# ESP32-P4 register map
Vendor: ESPRESSIF SYSTEMS (SHANGHAI) CO., LTD.; Series: ESP32 P-Series; File version: 3
CPU: RV32IMAFC r0p0, little endian, no MPU, FPU, 0 interrupt priority bits
Address unit: 32 bits
Registers are 32-bit, read-write, reset 0x0 unless marked. A register's access mark holds for its fields unless they carry their own. Offsets are from the block's base; [hi:lo] are bit positions; {n}, {i} and the like mark numbered series; <NAME> marks a mode.

## AHB_DMA — AHB_DMA Peripheral
Base 0x50085000
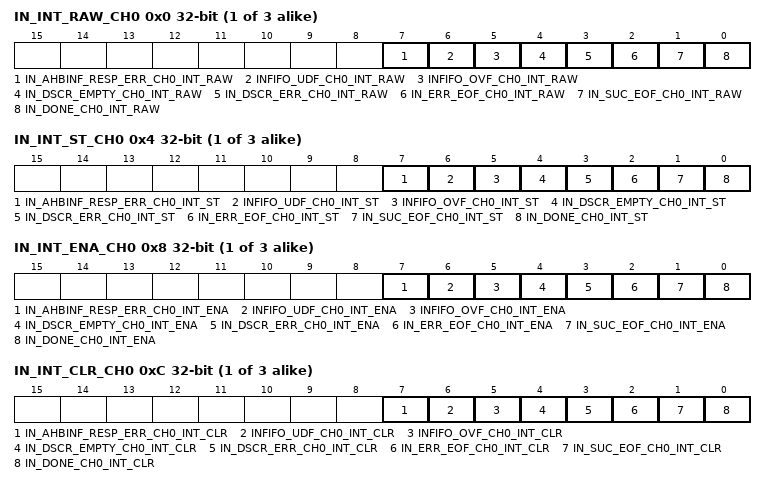
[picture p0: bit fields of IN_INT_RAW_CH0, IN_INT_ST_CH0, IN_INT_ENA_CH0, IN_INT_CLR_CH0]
{0x0+0x10*i} IN_INT_RAW_CH{i} (i=0..2) — Raw interrupt status of RX channel {i}
  [7] IN_AHBINF_RESP_ERR_CH{i}_INT_RAW — The raw interrupt status of AHB_DMA_IN_RESP_ERR_CH{i}_INT
  [6] INFIFO_UDF_CH{i}_INT_RAW — The raw interrupt status of AHB_DMA_INFIFO_UDF_CH{i}_INT
  [5] INFIFO_OVF_CH{i}_INT_RAW — The raw interrupt status of AHB_DMA_INFIFO_OVF_CH{i}_INT
  [4] IN_DSCR_EMPTY_CH{i}_INT_RAW — The raw interrupt status of AHB_DMA_IN_DSCR_EMPTY_CH{i}_INT
  [3] IN_DSCR_ERR_CH{i}_INT_RAW — The raw interrupt status of AHB_DMA_IN_DSCR_ERR_CH{i}_INT
  [2] IN_ERR_EOF_CH{i}_INT_RAW — The raw interrupt status of AHB_DMA_IN_ERR_EOF_CH{i}_INT
  [1] IN_SUC_EOF_CH{i}_INT_RAW — The raw interrupt status of AHB_DMA_IN_SUC_EOF_CH{i}_INT
  [0] IN_DONE_CH{i}_INT_RAW — The raw interrupt status of AHB_DMA_IN_DONE_CH{i}_INT
{0x4+0x10*i} IN_INT_ST_CH{i} ro (i=0..2) — Masked interrupt status of RX channel {i}
  [7] IN_AHBINF_RESP_ERR_CH{i}_INT_ST — The masked interrupt status of AHB_DMA_IN_RESP_ERR_CH{i}_INT
  [6] INFIFO_UDF_CH{i}_INT_ST — The masked interrupt status of AHB_DMA_INFIFO_UDF_CH{i}_INT
  [5] INFIFO_OVF_CH{i}_INT_ST — The masked interrupt status of AHB_DMA_INFIFO_OVF_CH{i}_INT
  [4] IN_DSCR_EMPTY_CH{i}_INT_ST — The masked interrupt status of AHB_DMA_IN_DSCR_EMPTY_CH{i}_INT
  [3] IN_DSCR_ERR_CH{i}_INT_ST — The masked interrupt status of AHB_DMA_IN_DSCR_ERR_CH{i}_INT
  [2] IN_ERR_EOF_CH{i}_INT_ST — The masked interrupt status of AHB_DMA_IN_ERR_EOF_CH{i}_INT
  [1] IN_SUC_EOF_CH{i}_INT_ST — The masked interrupt status of AHB_DMA_IN_SUC_EOF_CH{i}_INT
  [0] IN_DONE_CH{i}_INT_ST — The masked interrupt status of AHB_DMA_IN_DONE_CH{i}_INT
{0x8+0x10*i} IN_INT_ENA_CH{i} (i=0..2) — Interrupt enable bits of RX channel {i}
  [7] IN_AHBINF_RESP_ERR_CH{i}_INT_ENA — Write 1 to enable AHB_DMA_IN_RESP_ERR_CH{i}_INT
  [6] INFIFO_UDF_CH{i}_INT_ENA — Write 1 to enable AHB_DMA_INFIFO_UDF_CH{i}_INT
  [5] INFIFO_OVF_CH{i}_INT_ENA — Write 1 to enable AHB_DMA_INFIFO_OVF_CH{i}_INT
  [4] IN_DSCR_EMPTY_CH{i}_INT_ENA — Write 1 to enable AHB_DMA_IN_DSCR_EMPTY_CH{i}_INT
  [3] IN_DSCR_ERR_CH{i}_INT_ENA — Write 1 to enable AHB_DMA_IN_DSCR_ERR_CH{i}_INT
  [2] IN_ERR_EOF_CH{i}_INT_ENA — Write 1 to enable AHB_DMA_IN_ERR_EOF_CH{i}_INT
  [1] IN_SUC_EOF_CH{i}_INT_ENA — Write 1 to enable AHB_DMA_IN_SUC_EOF_CH{i}_INT
  [0] IN_DONE_CH{i}_INT_ENA — Write 1 to enable AHB_DMA_IN_DONE_CH{i}_INT
{0xC+0x10*i} IN_INT_CLR_CH{i} wo (i=0..2) — Interrupt clear bits of RX channel {i}
  [7] IN_AHBINF_RESP_ERR_CH{i}_INT_CLR — Write 1 to clear AHB_DMA_IN_RESP_ERR_CH{i}_INT
  [6] INFIFO_UDF_CH{i}_INT_CLR — Write 1 to clear AHB_DMA_INFIFO_UDF_CH{i}_INT
  [5] INFIFO_OVF_CH{i}_INT_CLR — Write 1 to clear AHB_DMA_INFIFO_OVF_CH{i}_INT
  [4] IN_DSCR_EMPTY_CH{i}_INT_CLR — Write 1 to clear AHB_DMA_IN_DSCR_EMPTY_CH{i}_INT
  [3] IN_DSCR_ERR_CH{i}_INT_CLR — Write 1 to clear AHB_DMA_IN_DSCR_ERR_CH{i}_INT
  [2] IN_ERR_EOF_CH{i}_INT_CLR — Write 1 to clear AHB_DMA_IN_ERR_EOF_CH{i}_INT
  [1] IN_SUC_EOF_CH{i}_INT_CLR — Write 1 to clear AHB_DMA_IN_SUC_EOF_CH{i}_INT
  [0] IN_DONE_CH{i}_INT_CLR — Write 1 to clear AHB_DMA_IN_DONE_CH{i}_INT
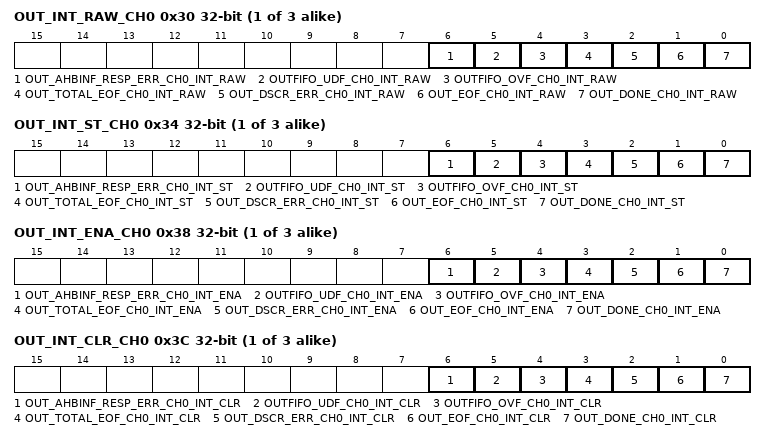
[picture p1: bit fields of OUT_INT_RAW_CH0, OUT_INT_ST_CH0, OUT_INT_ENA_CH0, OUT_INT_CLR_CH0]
{0x30+0x10*i} OUT_INT_RAW_CH{i} (i=0..2) — //Raw interrupt status of TX channel {i}
  [6] OUT_AHBINF_RESP_ERR_CH{i}_INT_RAW — The raw interrupt status of AHB_DMA_OUT_RESP_ERR_CH{i}_INT
  [5] OUTFIFO_UDF_CH{i}_INT_RAW — The raw interrupt status of AHB_DMA_OUTFIFO_UDF_CH{i}_INT
  [4] OUTFIFO_OVF_CH{i}_INT_RAW — The raw interrupt status of AHB_DMA_OUTFIFO_OVF_CH{i}_INT
  [3] OUT_TOTAL_EOF_CH{i}_INT_RAW — The raw interrupt status of AHB_DMA_OUT_TOTAL_EOF_CH{i}_INT
  [2] OUT_DSCR_ERR_CH{i}_INT_RAW — The raw interrupt status of AHB_DMA_OUT_DSCR_ERR_CH{i}_INT
  [1] OUT_EOF_CH{i}_INT_RAW — The raw interrupt status of AHB_DMA_OUT_EOF_CH{i}_INT
  [0] OUT_DONE_CH{i}_INT_RAW — The raw interrupt status of AHB_DMA_OUT_DONE_CH{i}_INT
{0x34+0x10*i} OUT_INT_ST_CH{i} ro (i=0..2) — Masked interrupt status of TX channel {i}
  [6] OUT_AHBINF_RESP_ERR_CH{i}_INT_ST — The masked interrupt status of AHB_DMA_OUT_RESP_ERR_CH{i}_INT
  [5] OUTFIFO_UDF_CH{i}_INT_ST — The masked interrupt status of AHB_DMA_OUTFIFO_UDF_CH{i}_INT
  [4] OUTFIFO_OVF_CH{i}_INT_ST — The masked interrupt status of AHB_DMA_OUTFIFO_OVF_CH{i}_INT
  [3] OUT_TOTAL_EOF_CH{i}_INT_ST — The masked interrupt status of AHB_DMA_OUT_TOTAL_EOF_CH{i}_INT
  [2] OUT_DSCR_ERR_CH{i}_INT_ST — The masked interrupt status of AHB_DMA_OUT_DSCR_ERR_CH{i}_INT
  [1] OUT_EOF_CH{i}_INT_ST — The masked interrupt status of AHB_DMA_OUT_EOF_CH{i}_INT
  [0] OUT_DONE_CH{i}_INT_ST — The masked interrupt status of AHB_DMA_OUT_DONE_CH{i}_INT
{0x38+0x10*i} OUT_INT_ENA_CH{i} (i=0..2) — Interrupt enable bits of TX channel {i}
  [6] OUT_AHBINF_RESP_ERR_CH{i}_INT_ENA — Write 1 to enable AHB_DMA_OUT_RESP_ERR_CH{i}_INT
  [5] OUTFIFO_UDF_CH{i}_INT_ENA — Write 1 to enable AHB_DMA_OUTFIFO_UDF_CH{i}_INT
  [4] OUTFIFO_OVF_CH{i}_INT_ENA — Write 1 to enable AHB_DMA_OUTFIFO_OVF_CH{i}_INT
  [3] OUT_TOTAL_EOF_CH{i}_INT_ENA — Write 1 to enable AHB_DMA_OUT_TOTAL_EOF_CH{i}_INT
  [2] OUT_DSCR_ERR_CH{i}_INT_ENA — Write 1 to enable AHB_DMA_OUT_DSCR_ERR_CH{i}_INT
  [1] OUT_EOF_CH{i}_INT_ENA — Write 1 to enable AHB_DMA_OUT_EOF_CH{i}_INT
  [0] OUT_DONE_CH{i}_INT_ENA — Write 1 to enable AHB_DMA_OUT_DONE_CH{i}_INT
{0x3C+0x10*i} OUT_INT_CLR_CH{i} wo (i=0..2) — Interrupt clear bits of TX channel {i}
  [6] OUT_AHBINF_RESP_ERR_CH{i}_INT_CLR — Write 1 to clear AHB_DMA_OUT_RESP_ERR_CH{i}_INT
  [5] OUTFIFO_UDF_CH{i}_INT_CLR — Write 1 to clear AHB_DMA_OUTFIFO_UDF_CH{i}_INT
  [4] OUTFIFO_OVF_CH{i}_INT_CLR — Write 1 to clear AHB_DMA_OUTFIFO_OVF_CH{i}_INT
  [3] OUT_TOTAL_EOF_CH{i}_INT_CLR — Write 1 to clear AHB_DMA_OUT_TOTAL_EOF_CH{i}_INT
  [2] OUT_DSCR_ERR_CH{i}_INT_CLR — Write 1 to clear AHB_DMA_OUT_DSCR_ERR_CH{i}_INT
  [1] OUT_EOF_CH{i}_INT_CLR — Write 1 to clear AHB_DMA_OUT_EOF_CH{i}_INT
  [0] OUT_DONE_CH{i}_INT_CLR — Write 1 to clear AHB_DMA_OUT_DONE_CH{i}_INT
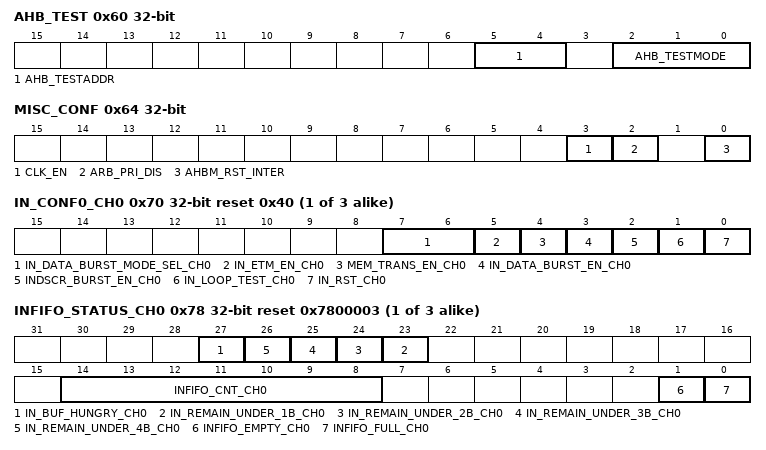
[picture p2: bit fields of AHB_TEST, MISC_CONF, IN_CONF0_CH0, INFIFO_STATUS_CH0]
0x60 AHB_TEST — only for test
  [5:4] AHB_TESTADDR — reserved
  [2:0] AHB_TESTMODE — reserved
0x64 MISC_CONF — reserved
  [3] CLK_EN — Configures clock gating.\\0: Support clock only when the application writes registers.\\ 1: Always force the clock on for registers.\\
  [2] ARB_PRI_DIS — Configures whether to disable the fixed-priority channel arbitration.\\0: Enable\\1: Disable\\
  [0] AHBM_RST_INTER — Write 1 and then 0 to reset the internal AHB FSM
0x68 DATE reset 0x250220 — Version control register
{0x70+0xC0*i} IN_CONF0_CH{i} reset 0x40 (i=0..2) — Configuration register 0 of RX channel {i}
  [7:6] IN_DATA_BURST_MODE_SEL_CH{i} — Configures max burst size for Rx channel{i}.\\2'b00: single\\ 2'b01: incr4\\ 2'b10: incr8\\ 2'b11: incr16\\
  [5] IN_ETM_EN_CH{i} — Configures whether to enable ETM control for RX channel{i}.\\0: Disable\\1: Enable\\
  [4] MEM_TRANS_EN_CH{i} — Configures whether to enable memory-to-memory data transfer.\\0: Disable\\1: Enable\\
  [3] IN_DATA_BURST_EN_CH{i} — Set this bit to 1 to enable INCR4 burst transfer for Rx channel {i} receiving data when accessing internal SRAM.
  [2] INDSCR_BURST_EN_CH{i} — Configures whether to enable INCR burst transfer for RX channel {i} to read descriptors.\\0: Disable\\1: Enable\\
  [1] IN_LOOP_TEST_CH{i} — reserved
  [0] IN_RST_CH{i} — Write 1 and then 0 to reset AHB_DMA channel {i} RX FSM and RX FIFO pointer.
{0x74+0xC0*i} IN_CONF1_CH{i} (i=0..2) — Configuration register 1 of RX channel {i}
  [12] IN_CHECK_OWNER_CH{i} — Configures whether to enable owner bit check for RX channel {i}.\\0: Disable\\1: Enable\\
{0x78+0xC0*i} INFIFO_STATUS_CH{i} ro reset 0x7800003 (i=0..2) — Receive FIFO status of RX channel {i}
  [27] IN_BUF_HUNGRY_CH{i} — reserved
  [n+22] IN_REMAIN_UNDER_{n}B_CH{i} (n=1..4) — reserved
  [14:8] INFIFO_CNT_CH{i} — Represents the number of data bytes in L1 RX FIFO for RX channel {i}
  [1] INFIFO_EMPTY_CH{i} — Represents whether L1 RX FIFO is empty.\\0: Not empty\\1: Empty\\
  [0] INFIFO_FULL_CH{i} — Represents whether L1 RX FIFO is full.\\0: Not Full\\1: Full\\
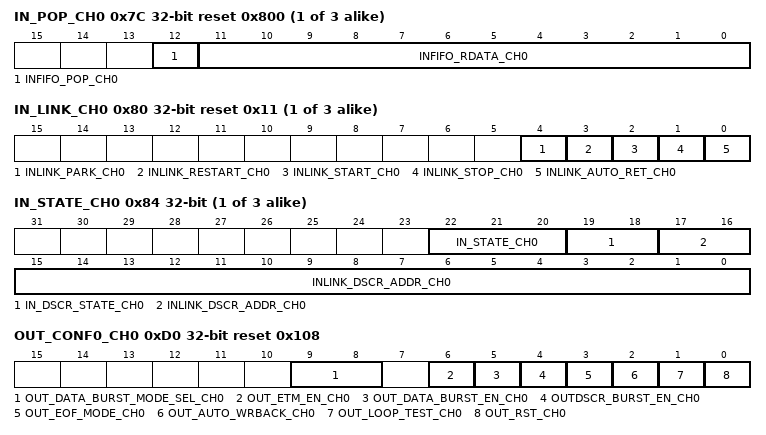
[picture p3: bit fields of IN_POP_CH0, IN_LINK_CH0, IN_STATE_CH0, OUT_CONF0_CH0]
{0x7C+0xC0*i} IN_POP_CH{i} access per field reset 0x800 (i=0..2) — Receive FIFO status of RX channel {i}
  [12] INFIFO_POP_CH{i} wo — Configures whether to pop data from AHB_DMA FIFO.\\0: Invalid. No effect\\1: Pop\\
  [11:0] INFIFO_RDATA_CH{i} ro — Represents the data popped from AHB_DMA FIFO.
{0x80+0xC0*i} IN_LINK_CH{i} access per field reset 0x11 (i=0..2) — Receive FIFO status of RX channel {i}
  [4] INLINK_PARK_CH{i} ro — Represents the status of the receive descriptor's FSM.\\0: Running\\1: Idle\\
  [3] INLINK_RESTART_CH{i} wo — Configures whether to restart RX channel {i} for AHB_DMA transfer.\\0: Invalid. No effect\\1: Restart\\
  [2] INLINK_START_CH{i} wo — Configures whether to enable AHB_DMA's RX channel {i} for data transfer.\\0: Disable\\1: Enable\\
  [1] INLINK_STOP_CH{i} wo — Configures whether to stop AHB_DMA's RX channel {i} from receiving data.\\0: Invalid. No effect\\1: Stop\\
  [0] INLINK_AUTO_RET_CH{i} rw — Configures whether to return to current receive descriptor's address when there are some errors in current receiving data.\\0: Not return\\1: Return\\.
{0x84+0xC0*i} IN_STATE_CH{i} ro (i=0..2) — Receive status of RX channel {i}
  [22:20] IN_STATE_CH{i} — Represents the address of the lower 18 bits of the next receive descriptor to be processed.
  [19:18] IN_DSCR_STATE_CH{i} — reserved
  [17:0] INLINK_DSCR_ADDR_CH{i} — reserved
{0x88+0xC0*i} IN_SUC_EOF_DES_ADDR_CH{i} ro (i=0..2) — Receive descriptor address when EOF occurs on RX channel {i}
  [31:0] IN_SUC_EOF_DES_ADDR_CH{i} — Represents the address of the receive descriptor when the EOF bit in this descriptor is 1.
{0x8C+0xC0*i} IN_ERR_EOF_DES_ADDR_CH{i} ro (i=0..2) — Receive descriptor address when errors occur of RX channel {i}
  [31:0] IN_ERR_EOF_DES_ADDR_CH{i} — Represents the address of the receive descriptor when there are some errors in the currently received data.
{0x90+0xC0*i} IN_DSCR_CH{i} ro (i=0..2) — Current receive descriptor address of RX channel {i}
  [31:0] INLINK_DSCR_CH{i} — Represents the address of the next receive descriptor x+1 pointed by the current receive descriptor that has already been fetched.
{0x94+0xC0*i} IN_DSCR_BF0_CH{i} ro (i=0..2) — The last receive descriptor address of RX channel {i}
  [31:0] INLINK_DSCR_BF0_CH{i} — Represents the address of the current receive descriptor x that has already been fetched.
{0x98+0xC0*i} IN_DSCR_BF1_CH{i} ro (i=0..2) — The second-to-last receive descriptor address of RX channel {i}
  [31:0] INLINK_DSCR_BF1_CH{i} — Represents the address of the previous receive descriptor x-1 that has already been fetched.
{0x9C+0xC0*i} IN_PERI_CH{i} (i=0..2) — Priority register of RX channel {i}
  [3:0] RX_PRI_CH{i} — Configures the priority of RX channel {i}.The larger of the value, the higher of the priority..
{0xA0+0xC0*i} IN_PERI_SEL_CH{i} reset 0x3F (i=0..2) — Peripheral selection register of RX channel {i}
  [5:0] PERI_IN_SEL_CH{i} — Configures the peripheral connected to RX channel {i}.\\ 0: I3C\\ 1: Dummy\\ 2: UHCI0\\ 3: I2S0\\ 4: I2S1\\ 5: I2S2\\ 6: Dummy\\ 7: Dummy\\ 8: ADC_DAC\\ 9: Dummy\\ 10: RMT\\ 11~15: Dummy\\
0xD0 OUT_CONF0_CH0 reset 0x108 — Configuration register 0 of TX channel 0
  [9:8] OUT_DATA_BURST_MODE_SEL_CH0 — Configures max burst size for TX channel0.\\2'b00: single\\ 2'b01: incr4\\ 2'b10: incr8\\ 2'b11: incr16\\
  [6] OUT_ETM_EN_CH0 — Configures whether to enable ETM control for TX channel 0.\\0: Disable\\1: Enable\\
  [5] OUT_DATA_BURST_EN_CH0 — Set this bit to 1 to enable INCR4 burst transfer for Tx channel 0 transmitting data when accessing internal SRAM.
  [4] OUTDSCR_BURST_EN_CH0 — Configures whether to enable INCR burst transfer for TX channel 0 reading descriptors.\\0: Disable\\1: Enable\\
  [3] OUT_EOF_MODE_CH0 — Configures when to generate EOF flag.\\0: EOF flag for TX channel 0 is generated when data to be transmitted has been pushed into FIFO in AHB_DMA.\\ 1: EOF flag for TX channel 0 is generated when data to be transmitted has been popped from FIFO in AHB_DMA.\\
  [2] OUT_AUTO_WRBACK_CH0 — Configures whether to enable automatic outlink write-back when all the data in TX FIFO has been transmitted.\\0: Disable\\1: Enable\\
  [1] OUT_LOOP_TEST_CH0 — reserved
  [0] OUT_RST_CH0 — Configures the reset state of AHB_DMA channel 0 TX FSM and TX FIFO pointer.\\0: Release reset\\1: Reset\\
{0xD4+0xC0*i} OUT_CONF1_CH{i} (i=0..2) — Configuration register 1 of TX channel {i}
  [12] OUT_CHECK_OWNER_CH{i} — Configures whether to enable owner bit check for TX channel {i}.\\0: Disable\\1: Enable\\
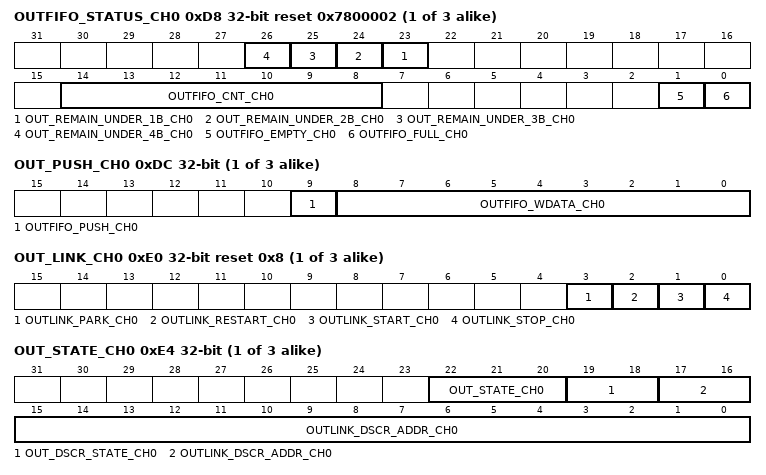
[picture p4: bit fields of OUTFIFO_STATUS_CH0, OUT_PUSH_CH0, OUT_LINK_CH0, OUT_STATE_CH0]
{0xD8+0xC0*i} OUTFIFO_STATUS_CH{i} ro reset 0x7800002 (i=0..2) — Receive FIFO status of RX channel {i}
  [n+22] OUT_REMAIN_UNDER_{n}B_CH{i} (n=1..4) — reserved
  [14:8] OUTFIFO_CNT_CH{i} — Represents the number of data bytes in L1 TX FIFO for TX channel {i}
  [1] OUTFIFO_EMPTY_CH{i} — Represents whether L1 TX FIFO is empty.\\0: Not empty\\1: Empty\\
  [0] OUTFIFO_FULL_CH{i} — Represents whether L1 TX FIFO is full.\\0: Not Full\\1: Full\\
{0xDC+0xC0*i} OUT_PUSH_CH{i} access per field (i=0..2) — Push control register of TX channel {i}
  [9] OUTFIFO_PUSH_CH{i} wo — Configures the data that need to be pushed into AHB_DMA FIFO.
  [8:0] OUTFIFO_WDATA_CH{i} rw — Configures whether to push data into AHB_DMA FIFO.\\0: Invalid. No effect\\1: Push\\
{0xE0+0xC0*i} OUT_LINK_CH{i} access per field reset 0x8 (i=0..2) — Push control register of TX channel {i}
  [3] OUTLINK_PARK_CH{i} ro — Represents the status of the transmit descriptor's FSM.\\0: Running\\1: Idle\\
  [2] OUTLINK_RESTART_CH{i} wo — Configures whether to restart TX channel {i} for AHB_DMA transfer.\\0: Invalid. No effect\\1: Restart\\
  [1] OUTLINK_START_CH{i} wo — Configures whether to enable AHB_DMA's TX channel {i} for data transfer.\\0: Disable\\1: Enable\\
  [0] OUTLINK_STOP_CH{i} wo — Configures whether to stop AHB_DMA's TX channel {i} from transmitting data.\\0: Invalid. No effect\\1: Stop\\
{0xE4+0xC0*i} OUT_STATE_CH{i} ro (i=0..2) — Transmit status of TX channel {i}
  [22:20] OUT_STATE_CH{i} — reserved
  [19:18] OUT_DSCR_STATE_CH{i} — reserved
  [17:0] OUTLINK_DSCR_ADDR_CH{i} — Represents the lower 18 bits of the address of the next transmit descriptor to be processed.
{0xE8+0xC0*i} OUT_EOF_DES_ADDR_CH{i} ro (i=0..2) — Transmit descriptor address when EOF occurs on TX channel {i}
  [31:0] OUT_EOF_DES_ADDR_CH{i} — Represents the address of the transmit descriptor when the EOF bit in this descriptor is 1.
{0xEC+0xC0*i} OUT_EOF_BFR_DES_ADDR_CH{i} ro (i=0..2) — The last transmit descriptor address when EOF occurs on TX channel {i}
  [31:0] OUT_EOF_BFR_DES_ADDR_CH{i} — Represents the address of the transmit descriptor before the last transmit descriptor.
{0xF0+0xC0*i} OUT_DSCR_CH{i} ro (i=0..2) — Current transmit descriptor address of TX channel {i}
  [31:0] OUTLINK_DSCR_CH{i} — Represents the address of the next transmit descriptor y+1 pointed by the current transmit descriptor that has already been fetched.
{0xF4+0xC0*i} OUT_DSCR_BF0_CH{i} ro (i=0..2) — The last transmit descriptor address of TX channel {i}
  [31:0] OUTLINK_DSCR_BF0_CH{i} — Represents the address of the current transmit descriptor y that has already been fetched.
{0xF8+0xC0*i} OUT_DSCR_BF1_CH{i} ro (i=0..2) — The second-to-last transmit descriptor address of TX channel {i}
  [31:0] OUTLINK_DSCR_BF1_CH{i} — Represents the address of the previous transmit descriptor y-1 that has already been fetched.
{0xFC+0xC0*i} OUT_PERI_CH{i} (i=0..2) — Priority register of TX channel {i}
  [3:0] TX_PRI_CH{i} — Configures the priority of TX channel {i}.The larger of the value, the higher of the priority..
{0x100+0xC0*i} OUT_PERI_SEL_CH{i} reset 0x3F (i=0..2) — Peripheral selection register of TX channel {i}
  [5:0] PERI_OUT_SEL_CH{i} — Configures the peripheral connected to TX channel {i}.\\ 0: I3C\\ 1: Dummy\\ 2: UHCI0\\ 3: I2S0\\ 4: I2S1\\ 5: I2S2\\ 6: Dummy\\ 7: Dummy\\ 8: ADC_DAC\\ 9: Dummy\\ 10: RMT\\ 11~15: Dummy\\
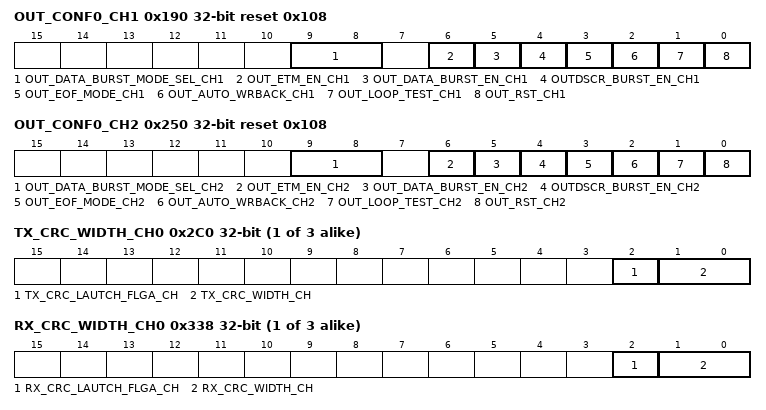
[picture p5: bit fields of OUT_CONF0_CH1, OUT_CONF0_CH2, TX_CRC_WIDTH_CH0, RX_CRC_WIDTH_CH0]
0x190 OUT_CONF0_CH1 reset 0x108 — Configuration register 0 of TX channel 1
  [9:8] OUT_DATA_BURST_MODE_SEL_CH1 — Configures max burst size for TX channel1.\\2'b00: single\\ 2'b01: incr4\\ 2'b10: incr8\\ 2'b11: incr16\\
  [6] OUT_ETM_EN_CH1 — Configures whether to enable ETM control for TX channel 1.\\0: Disable\\1: Enable\\
  [5] OUT_DATA_BURST_EN_CH1 — Set this bit to 1 to enable INCR burst transfer for Tx channel 1 transmitting data when accessing internal SRAM.
  [4] OUTDSCR_BURST_EN_CH1 — Configures whether to enable INCR burst transfer for TX channel 1 reading descriptors.\\0: Disable\\1: Enable\\
  [3] OUT_EOF_MODE_CH1 — Configures when to generate EOF flag.\\0: EOF flag for TX channel 1 is generated when data to be transmitted has been pushed into FIFO in AHB_DMA.\\ 1: EOF flag for TX channel 1 is generated when data to be transmitted has been popped from FIFO in AHB_DMA.\\
  [2] OUT_AUTO_WRBACK_CH1 — Configures whether to enable automatic outlink write-back when all the data in TX FIFO has been transmitted.\\0: Disable\\1: Enable\\
  [1] OUT_LOOP_TEST_CH1 — reserved
  [0] OUT_RST_CH1 — Configures the reset state of AHB_DMA channel 1 TX FSM and TX FIFO pointer.\\0: Release reset\\1: Reset\\
0x250 OUT_CONF0_CH2 reset 0x108 — Configuration register 0 of TX channel 2
  [9:8] OUT_DATA_BURST_MODE_SEL_CH2 — Configures max burst size for TX channel2.\\2'b00: single\\ 2'b01: incr4\\ 2'b10: incr8\\ 2'b11: incr16\\
  [6] OUT_ETM_EN_CH2 — Configures whether to enable ETM control for TX channel 2.\\0: Disable\\1: Enable\\
  [5] OUT_DATA_BURST_EN_CH2 — Set this bit to 1 to enable INCR burst transfer for Tx channel 2 transmitting data when accessing internal SRAM.
  [4] OUTDSCR_BURST_EN_CH2 — Configures whether to enable INCR burst transfer for TX channel 2 reading descriptors.\\0: Disable\\1: Enable\\
  [3] OUT_EOF_MODE_CH2 — Configures when to generate EOF flag.\\0: EOF flag for TX channel 2 is generated when data to be transmitted has been pushed into FIFO in AHB_DMA.\\ 1: EOF flag for TX channel 2 is generated when data to be transmitted has been popped from FIFO in AHB_DMA.\\
  [2] OUT_AUTO_WRBACK_CH2 — Configures whether to enable automatic outlink write-back when all the data in TX FIFO has been transmitted.\\0: Disable\\1: Enable\\
  [1] OUT_LOOP_TEST_CH2 — reserved
  [0] OUT_RST_CH2 — Configures the reset state of AHB_DMA channel 2 TX FSM and TX FIFO pointer.\\0: Release reset\\1: Reset\\
{0x2BC+0x28*i} OUT_CRC_INIT_DATA_CH{i} (i=0..2) reset 0xFFFFFFFF — This register is used to config ch{i} crc initial data(max 32 bit)
  [31:0] OUT_CRC_INIT_DATA_CH — This register is used to config ch0 of tx crc initial value
{0x2C0+0x28*i} TX_CRC_WIDTH_CH{i} (i=0..2) — This register is used to confiig tx ch{i} crc result width,2'b00 mean crc_width <=8bit,2'b01 8<crc_width<=16 ,2'b10 mean 16<crc_width <=24,2'b11 mean 24<crc_width<=32
  [2] TX_CRC_LAUTCH_FLGA_CH — reserved
  [1:0] TX_CRC_WIDTH_CH — reserved
{0x2C4+0x28*i} OUT_CRC_CLEAR_CH{i} (i=0..2) — This register is used to clear ch{i} crc result
  [0] OUT_CRC_CLEAR_CH — This register is used to clear ch0 of tx crc result
{0x2C8+0x28*i} OUT_CRC_FINAL_RESULT_CH{i} (i=0..2) ro — This register is used to store ch{i} crc result
  [31:0] OUT_CRC_FINAL_RESULT_CH — This register is used to store result ch0 of tx
{0x2CC+0x28*i} TX_CRC_EN_WR_DATA_CH{i} (i=0..2) — This resister is used to config ch{i} crc en for every bit
  [31:0] TX_CRC_EN_WR_DATA_CH — This register is used to enable tx ch0 crc 32bit on/off
{0x2D0+0x28*i} TX_CRC_EN_ADDR_CH{i} (i=0..2) — This register is used to config ch{i} crc en addr
  [31:0] TX_CRC_EN_ADDR_CH — reserved
{0x2D4+0x28*i} TX_CRC_DATA_EN_WR_DATA_CH{i} (i=0..2) — This register is used to config crc data_8bit en
  [7:0] TX_CRC_DATA_EN_WR_DATA_CH — reserved
{0x2D8+0x28*i} TX_CRC_DATA_EN_ADDR_CH{i} (i=0..2) — This register is used to config addr of crc data_8bit en
  [31:0] TX_CRC_DATA_EN_ADDR_CH — reserved
{0x2DC+0x28*i} TX_CH_ARB_WEIGHT_CH{i} (i=0..2) — TX channel {i} arbitration weight configuration register
  [3:0] TX_ARB_WEIGHT_VALUE_CH{i} — Configures the weight(i.e the number of tokens) of TX channel{i}
{0x2E0+0x28*i} TX_ARB_WEIGHT_OPT_DIR_CH{i} (i=0..2) — TX channel {i} weight arbitration optimization enable register
  [0] TX_ARB_WEIGHT_OPT_DIS_CH{i} — reserved
{0x334+0x28*i} IN_CRC_INIT_DATA_CH{i} (i=0..2) reset 0xFFFFFFFF — This register is used to config ch{i} crc initial data(max 32 bit)
  [31:0] IN_CRC_INIT_DATA_CH — This register is used to config ch0 of rx crc initial value
{0x338+0x28*i} RX_CRC_WIDTH_CH{i} (i=0..2) — This register is used to confiig rx ch{i} crc result width,2'b00 mean crc_width <=8bit,2'b01 8<crc_width<=16 ,2'b10 mean 16<crc_width <=24,2'b11 mean 24<crc_width<=32
  [2] RX_CRC_LAUTCH_FLGA_CH — reserved
  [1:0] RX_CRC_WIDTH_CH — reserved
{0x33C+0x28*i} IN_CRC_CLEAR_CH{i} (i=0..2) — This register is used to clear ch{i} crc result
  [0] IN_CRC_CLEAR_CH — This register is used to clear ch0 of rx crc result
{0x340+0x28*i} IN_CRC_FINAL_RESULT_CH{i} (i=0..2) ro — This register is used to store ch{i} crc result
  [31:0] IN_CRC_FINAL_RESULT_CH — This register is used to store result ch0 of rx
{0x344+0x28*i} RX_CRC_EN_WR_DATA_CH{i} (i=0..2) — This resister is used to config ch{i} crc en for every bit
  [31:0] RX_CRC_EN_WR_DATA_CH — This register is used to enable rx ch0 crc 32bit on/off
{0x348+0x28*i} RX_CRC_EN_ADDR_CH{i} (i=0..2) — This register is used to config ch{i} crc en addr
  [31:0] RX_CRC_EN_ADDR_CH — reserved
{0x34C+0x28*i} RX_CRC_DATA_EN_WR_DATA_CH{i} (i=0..2) — This register is used to config crc data_8bit en
  [7:0] RX_CRC_DATA_EN_WR_DATA_CH — reserved
{0x350+0x28*i} RX_CRC_DATA_EN_ADDR_CH{i} (i=0..2) — This register is used to config addr of crc data_8bit en
  [31:0] RX_CRC_DATA_EN_ADDR_CH — reserved
{0x354+0x28*i} RX_CH_ARB_WEIGHT_CH{i} (i=0..2) — RX channel {i} arbitration weight configuration register
  [3:0] RX_ARB_WEIGHT_VALUE_CH{i} — Configures the weight(i.e the number of tokens) of RX channel{i}
{0x358+0x28*i} RX_ARB_WEIGHT_OPT_DIR_CH{i} (i=0..2) — RX channel {i} weight arbitration optimization enable register
  [0] RX_ARB_WEIGHT_OPT_DIS_CH{i} — reserved
{0x3AC+4i} IN_LINK_ADDR_CH{i} (i=0..2) — Link list descriptor address configuration of RX channel {i}
  [31:0] INLINK_ADDR_CH{i} — Configures the 32 bits of the first receive descriptor's address
{0x3B8+4i} OUT_LINK_ADDR_CH{i} (i=0..2) — Link list descriptor address configuration of TX channel {i}
  [31:0] OUTLINK_ADDR_CH{i} — Configures the 32 bits of the first receive descriptor's address.
0x3C4 INTR_MEM_START_ADDR — Accessible address space start address configuration register
  [31:0] ACCESS_INTR_MEM_START_ADDR
0x3C8 INTR_MEM_END_ADDR reset 0xFFFFFFFF — Accessible address space end address configuration register
  [31:0] ACCESS_INTR_MEM_END_ADDR — Configures the end address of accessible address space.
0x3CC ARB_TIMEOUT_TX — TX arbitration timeout configuration register
  [15:0] ARB_TIMEOUT_TX — Configures the time slot for TX. Measurement unit: AHB bus clock cycle.
0x3D0 ARB_TIMEOUT_RX — RX arbitration timeout configuration register
  [15:0] ARB_TIMEOUT_RX — Configures the time slot for RX. Measurement unit: AHB bus clock cycle.
0x3D4 WEIGHT_EN_TX — TX weight arbitration enable register
  [0] WEIGHT_EN_TX — Configures whether to enable weight arbitration for TX.\\0: Disable\\1: Enable\\
0x3D8 WEIGHT_EN_RX — RX weight arbitration enable register
  [0] WEIGHT_EN_RX — Configures whether to enable weight arbitration for RX.\\0: Disable\\1: Enable\\
0x3DC ARB_TIMEOUT — TX arbitration timeout configuration register
  [15:0] NUM — Configures the time slot. Measurement unit: AHB bus clock cycle.
0x400 WEIGHT_EN — TX weight arbitration enable register
  [0] WEIGHT_EN — Configures whether to enable weight arbitration.\\0: Disable\\1: Enable\\
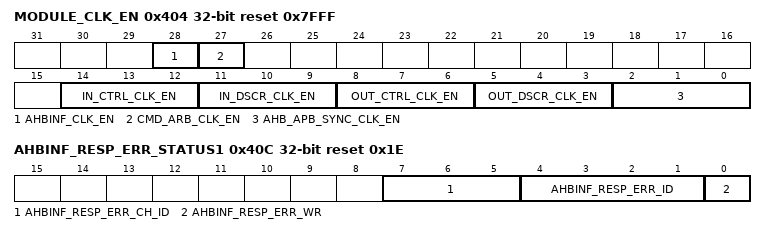
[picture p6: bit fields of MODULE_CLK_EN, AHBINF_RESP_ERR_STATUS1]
0x404 MODULE_CLK_EN reset 0x7FFF — Module clock force on register
  [28] AHBINF_CLK_EN — Configures whether to force on ahbinf module clock. \\0 : Not force on ahbinf clock \\1 : Force on ahbinf clock\\
  [27] CMD_ARB_CLK_EN — Configures whether to force on cmd_arb module clock. \\0 : Not force on cmd_arb clock \\1 : Force on cmd_arb clock\\
  [14:12] IN_CTRL_CLK_EN — Configures whether to force on in_ctrl 2~0 module clock. For bit n:\\0 : Not force on in_ctrl n clock \\1 : Force on in_ctrl n clock\\
  [11:9] IN_DSCR_CLK_EN — Configures whether to force on in_dscr 2~0 module clock. For bit n:\\0 : Not force on in_dscr n clock \\1 : Force on in_dscr n clock\\
  [8:6] OUT_CTRL_CLK_EN — Configures whether to force on out_ctrl 2~0 module clock. For bit n:\\0 : Not force on out_ctrl n clock \\1 : Force on out_ctrl n clock\\
  [5:3] OUT_DSCR_CLK_EN — Configures whether to force on out_dscr 2~0 module clock. For bit n:\\0 : Not force on out_dscr n clock \\1 : Force on out_dscr n clock\\
  [2:0] AHB_APB_SYNC_CLK_EN — Configures whether to force on ahb_apb_sync 2~0 module clock. For bit n:\\0 : Not force on ahb_apb_sync n clock \\1 : Force on ahb_apb_sync n clock\\
0x408 AHBINF_RESP_ERR_STATUS0 ro — AHB response error status 0 register
  [31:0] AHBINF_RESP_ERR_ADDR — Represents the address of the AHB response error.
0x40C AHBINF_RESP_ERR_STATUS1 ro reset 0x1E — AHB response error status 1 register
  [7:5] AHBINF_RESP_ERR_CH_ID — Represents the AHB response error request channel id.bit[2]=1:TX channel.\\bit[2]=0:RX channel.\\
  [4:1] AHBINF_RESP_ERR_ID — Represents the AHB response error request id.
  [0] AHBINF_RESP_ERR_WR — Represents the AHB response error is write request.
{0x410+8i} IN_DONE_DES_ADDR_CH{i} ro (i=0..2) — RX_done Inlink descriptor address of RX channel {i}
  [31:0] IN_DONE_DES_ADDR_CH{i} — Represents the address of the inlink descriptor when this descriptor is completed .
{0x414+8i} OUT_DONE_DES_ADDR_CH{i} ro (i=0..2) — TX done outlink descriptor address of TX channel {i}
  [31:0] OUT_DONE_DES_ADDR_CH{i} — Represents the address of the outlink descriptor when this descriptor is completed.

## Notices in the file
Copyright 2026 Espressif Systems (Shanghai) PTE LTD
Licensed under the Apache License, Version 2.0 (the "License");
you may not use this file except in compliance with the License.
You may obtain a copy of the License at
http://www.apache.org/licenses/LICENSE-2.0
Unless required by applicable law or agreed to in writing, software
distributed under the License is distributed on an "AS IS" BASIS,
WITHOUT WARRANTIES OR CONDITIONS OF ANY KIND, either express or implied.
See the License for the specific language governing permissions and
limitations under the License.
